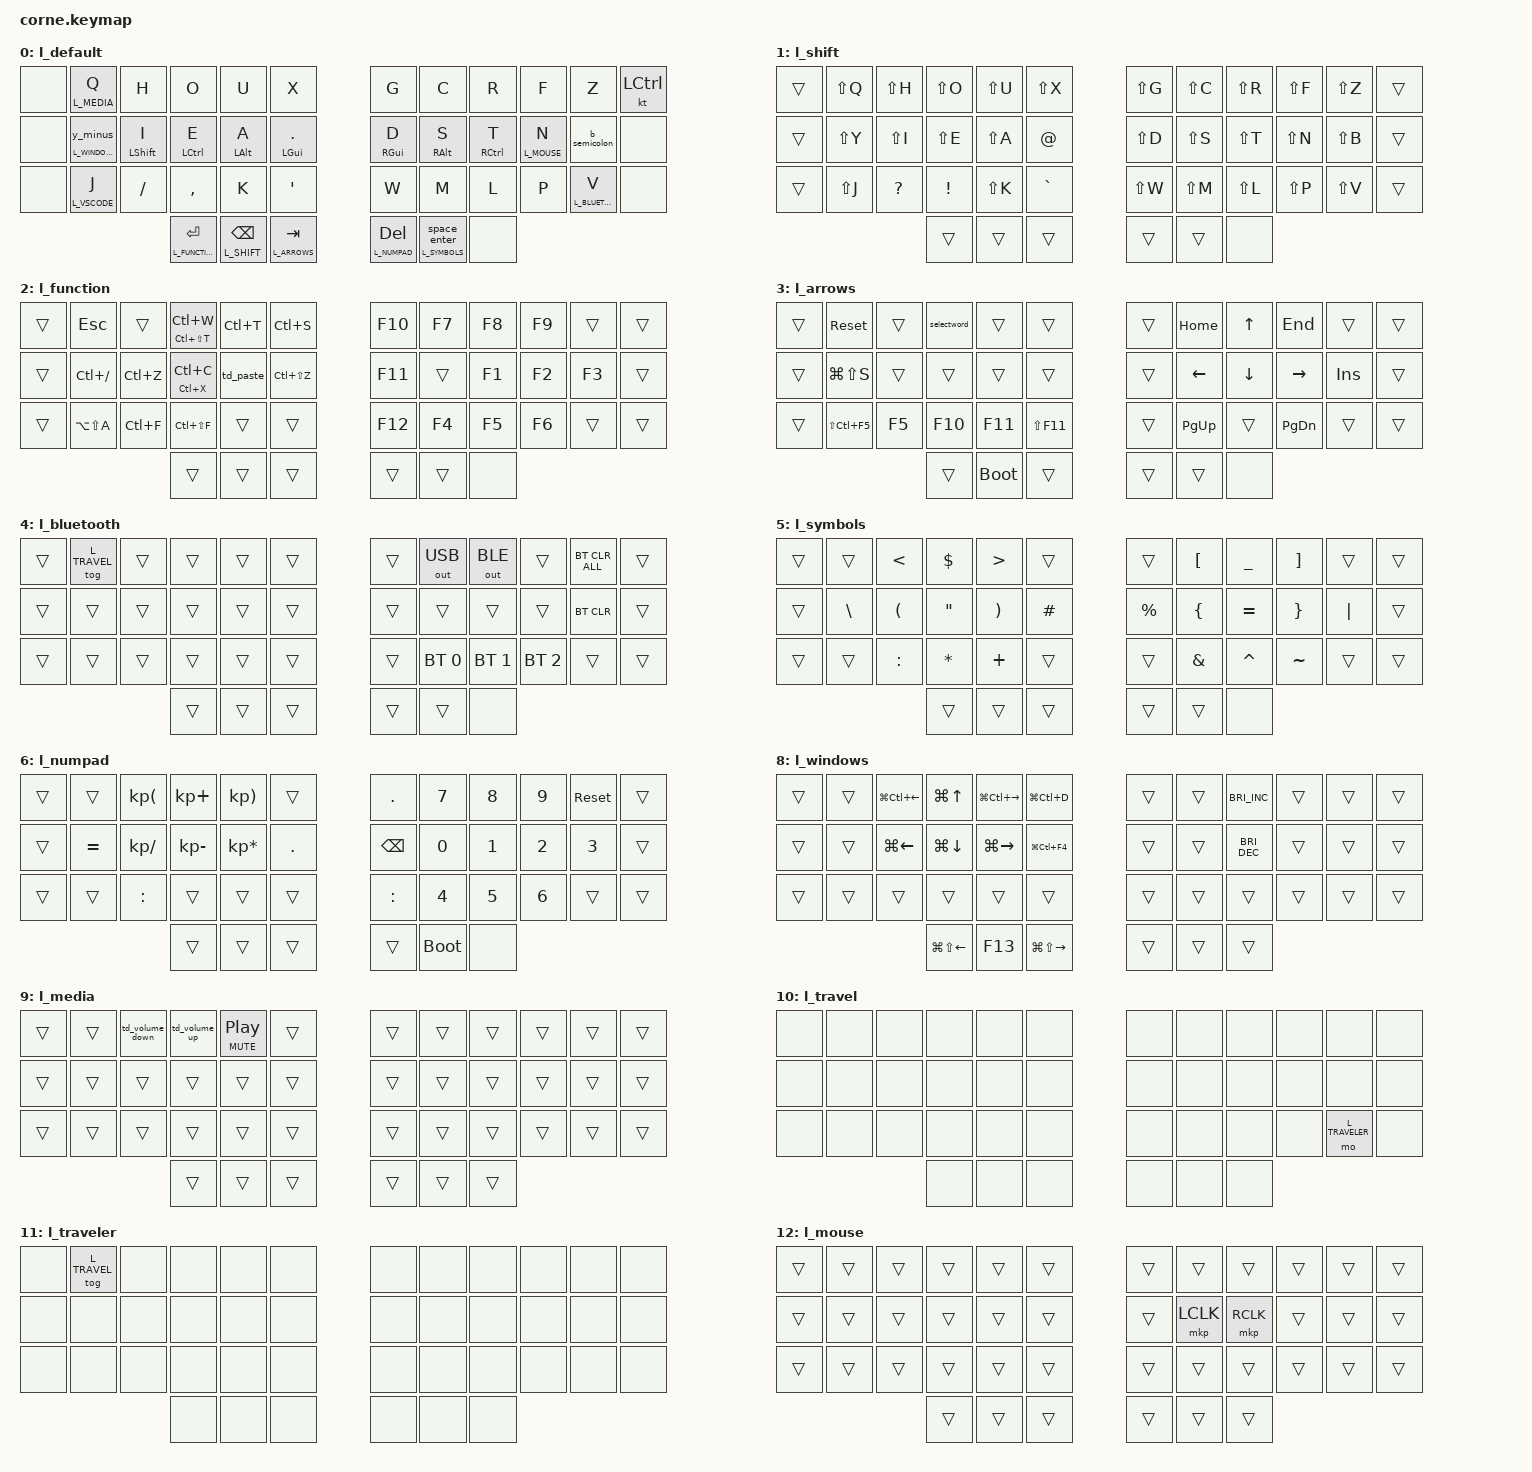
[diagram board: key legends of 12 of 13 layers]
/*
 * Copyright (c) 2020 The ZMK Contributors
 *
 * SPDX-License-Identifier: MIT
 */

#include <behaviors.dtsi>
#include <dt-bindings/zmk/keys.h> //https://zmk.dev/docs/codes
#include <dt-bindings/zmk/bt.h> //https://zmk.dev/docs/behaviors/bluetooth
#include <dt-bindings/zmk/ext_power.h> //https://zmk.dev/docs/behaviors/power
#include <dt-bindings/zmk/outputs.h> //https://zmk.dev/docs/behaviors/outputs
#include <dt-bindings/zmk/mouse.h> //https://zmk.dev/docs/behaviors/mouse-emulation

#define L_DEFAULT       0
#define L_SHIFT         1
#define L_FUNCTION      2
#define L_ARROWS        3
#define L_BLUETOOTH     4
#define L_SYMBOLS       5
#define L_NUMPAD        6
#define L_VSCODE        7
#define L_WINDOWS       8
#define L_MEDIA         9
#define L_TRAVEL       10
#define L_TRAVELER     11
#define L_MOUSE        12

&mt {
    tapping-term-ms = <200>; //default: 200
    flavor = "tap-preferred"; //default: hold-preferred
};
&lt {
    tapping-term-ms = <200>; //default: 200
    flavor = "hold-preferred"; //default: tap-preferred
    //quick-tap-ms = <200>; //allows backspace to be held by tapping and holding
    //FIXME: backspacing, followed by a hold (for the shift layer) behaves as a double backspace
};

/ {
        behaviors {
                //https://zmk.dev/docs/behaviors/hold-tap
                ht: hold_tap {
                        compatible = "zmk,behavior-hold-tap";
                        #binding-cells = <2>;
                        tapping-term-ms = <200>;
                        quick-tap-ms = <0>;
                        flavor = "tap-preferred";
                        bindings = <&kp>, <&kp>;
                };

                //https://zmk.dev/docs/behaviors/tap-dance
                td_paste: tap_dance_paste {
                        //single tap = paste, hold = clipboard history, double tap = paste without formatting
                        compatible = "zmk,behavior-tap-dance";
                        #binding-cells = <0>;
                        tapping-term-ms = <200>;
                        bindings = <&ht LC(LS(V)) LC(V)>, <&kp LG(V)>;
                };
                td_volume_up: tap_dance_volume_up {
                        //single tap = volume up, hold = next track, double tap = volume up
                        compatible = "zmk,behavior-tap-dance";
                        #binding-cells = <0>;
                        tapping-term-ms = <200>;
                        bindings = <&ht C_NEXT C_VOLUME_UP>, <&kp C_VOLUME_UP>;
                };
                td_volume_down: tap_dance_volume_down {
                        //single tap = volume down, hold = previous track, double tap = volume down
                        compatible = "zmk,behavior-tap-dance";
                        #binding-cells = <0>;
                        tapping-term-ms = <200>;
                        bindings = <&ht C_PREV C_VOLUME_DOWN>, <&kp C_VOLUME_DOWN>;
                };
                b_semicolon: b_semicolon {
                        compatible = "zmk,behavior-mod-morph";
                        #binding-cells = <0>;
                        bindings = <&kp B>, <&kp SEMICOLON>;
                        mods = <(MOD_LCTL)>;
                        keep-mods = <(MOD_RCTL)>;
                };
                y_minus: y_minus {
                        compatible = "zmk,behavior-mod-morph";
                        #binding-cells = <0>;
                        bindings = <&kp Y>, <&kp MINUS>;
                        mods = <(MOD_RCTL)>;
                        keep-mods = <(MOD_LCTL)>;
                };
                lt_y_minus: lt_y_minus {
                        compatible = "zmk,behavior-hold-tap";
                        label = "LT_Y_MINUS";
                        #binding-cells = <2>;
                        bindings = <&mo>, <&y_minus>;
                        tapping-term-ms = <200>;
                };
                space_enter: space_enter {
                        compatible = "zmk,behavior-mod-morph";
                        #binding-cells = <0>;
                        bindings = <&kp SPACE>, <&kp ENTER>;
                        mods = <(MOD_LCTL|MOD_RCTL)>;
                };
                lt_space_enter: lt_space_enter {
                        compatible = "zmk,behavior-hold-tap";
                        label = "LT_SPACE_ENTER";
                        #binding-cells = <2>;
                        bindings = <&mo>, <&space_enter>;
                        tapping-term-ms = <200>;
                };
        };

        macros {
                //https://zmk.dev/docs/behaviors/macros
                references: references {
                        compatible = "zmk,behavior-macro";
                        #binding-cells = <0>;
                        bindings
                                = <&macro_tap &kp LC(K) &kp LC(R)>
                                ;
                };
                prevbookmark: prevbookmark {
                        compatible = "zmk,behavior-macro";
                        #binding-cells = <0>;
                        bindings
                                = <&macro_tap &kp LC(B) &kp LC(P)>
                                ;
                };
                nextbookmark: nextbookmark {
                        compatible = "zmk,behavior-macro";
                        #binding-cells = <0>;
                        bindings
                                = <&macro_tap &kp LC(B) &kp LC(N)>
                                ;
                };
                selectword: selectword {
                        compatible = "zmk,behavior-macro";
                        #binding-cells = <0>;
                        bindings
                                = <&macro_tap &kp LC(LEFT) &kp LC(LS(RIGHT))>
                                ;
                };
    };

        keymap {
                compatible = "zmk,keymap";

                l_default {
// -----------------------------------------------------------------------------------------
// |   q   |  h  |  o  |  u  |  x  |                                        |  g  |  c  |  r  |  f  |  z  |
// |  y/-  |  i  |  e  |  a  |  .  |                                        |  d  |  s  |  t  |  n  | b/; |
// |   j   |  /  |  ,  |  k  |  '  |                                        |  w  |  m  |  l  |  p  |  v  |
//       | ENTER | BACKSPACE | TAB |                                        | DELETE | SPACE |
                        bindings = <
&none       &lt L_MEDIA Q               &kp H           &kp O                   &kp U                   &kp X                           &kp G                   &kp C                           &kp R                   &kp F           &kp Z               &kt LCTRL
&none       &lt_y_minus L_WINDOWS 0     &mt LSHFT I     &mt LCTRL E             &mt LALT A              &mt LGUI PERIOD                 &mt RGUI D              &mt RALT S                      &mt RCTRL T             &lt L_MOUSE N   &b_semicolon        &none
&none       &lt L_VSCODE J              &kp SLASH       &kp COMMA               &kp K                   &kp APOSTROPHE                  &kp W                   &kp M                           &kp L                   &kp P           &lt L_BLUETOOTH V   &none
                                                        &lt L_FUNCTION ENTER    &lt L_SHIFT BACKSPACE   &lt L_ARROWS TAB                &lt L_NUMPAD DELETE     &lt_space_enter L_SYMBOLS 0     &none
                        >;
                };
                l_shift {
// -----------------------------------------------------------------------------------------
// |  Q  |  H  |  O  |  U  |  X  |                                        |  G  |  C  |  R  |  F  |  Z  |
// |  Y  |  I  |  E  |  A  |  @  |                                        |  D  |  S  |  T  |  N  |  B  |
// |  J  |  ?  |  !  |  K  |  `  |                                        |  W  |  M  |  L  |  P  |  V  |
//             |     |  *  |     |                                        |     |     |
                        bindings = <
&trans  &kp LS(Q)       &kp LS(H)       &kp LS(O)       &kp LS(U)       &kp LS(X)               &kp LS(G)       &kp LS(C)       &kp LS(R)       &kp LS(F)       &kp LS(Z)       &trans
&trans  &kp LS(Y)       &kp LS(I)       &kp LS(E)       &kp LS(A)       &kp AT                  &kp LS(D)       &kp LS(S)       &kp LS(T)       &kp LS(N)       &kp LS(B)       &trans
&trans  &kp LS(J)       &kp QMARK       &kp EXCL        &kp LS(K)       &kp GRAVE               &kp LS(W)       &kp LS(M)       &kp LS(L)       &kp LS(P)       &kp LS(V)       &trans
                                        &trans          &trans          &trans                  &trans          &trans          &none
                        >;
                };
                l_function {
// -----------------------------------------------------------------------------------------
// |ESC            |       |CLOSE TAB              |NEW TAB        |SAVE        |               |F10|F7 |F8 |F9 |   |
// |LINE COMMENT   |UNDO   |COPY                   |PASTE          |REDO        |               |F11|   |F1 |F2 |F3 |
// |BLOCK COMMENT  |FIND   |FIND IN SOLUTION       |               |            |               |F12|F4 |F5 |F6 |   |
//                         |           *           |               |            |               |   |   |
                        bindings = <
&trans      &kp ESC          &trans          &ht LC(LS(T)) LC(W)     &kp LC(T)               &kp LC(S)               &kp F10 &kp F7  &kp F8  &kp F9  &trans  &trans
&trans      &kp LC(SLASH)   &kp LC(Z)       &ht LC(X) LC(C)         &td_paste               &kp LC(LS(Z))           &kp F11 &trans  &kp F1  &kp F2  &kp F3  &trans
&trans      &kp LA(LS(A))   &kp LC(F)       &kp LC(LS(F))           &trans                  &trans                  &kp F12 &kp F4  &kp F5  &kp F6  &trans  &trans
                                            &trans                  &trans                  &trans                  &trans  &trans  &none
                        >;
                };
                l_arrows {
// -----------------------------------------------------------------------------------------
// | RESET      |                | SELECT WORD |         |          |                        |    |HOME    |UP     |END       |       |
// | SCREENSHOT | SHIFT          | CTRL        | ALT     |          |                        |    |LEFT    |DOWN   |RIGHT     |INSERT |
// | RESTART    | DEBUG/CONTINUE | STEP        | STEP IN | STEP OUT |                        |    |PAGE UP |       |PAGE DOWN |       |
//                               |             | BOOT    |     *    |                        |    |        |
                        bindings = <
&trans  &sys_reset          &trans  &selectword     &trans        &trans                  &trans  &kp HOME        &kp UP          &kp END         &trans          &trans
&trans  &kp LG(LS(S))   &trans  &trans          &trans        &trans                  &trans  &kp LEFT        &kp DOWN        &kp RIGHT       &kp INSERT      &trans
&trans  &kp LS(LC(F5))  &kp F5  &kp F10         &kp F11       &kp LS(F11)             &trans  &kp PG_UP       &trans          &kp PG_DN       &trans          &trans
                                &trans          &bootloader   &trans                  &trans  &trans          &none
                        >;
                };

                l_bluetooth 
                {
                        //https://zmk.dev/docs/behaviors/bluetooth
// -----------------------------------------------------------------------------------------
// |TRAVEL TOG  |    |    |    |    |                        |    | USB   | BLE   |      | CLEAR ALL |
// |            |    |    |    |    |                        |    |       |       |      | CLEAR     |
// |            |    |    |    |    |                        |    | SEL 0 | SEL 1 | SEL2 |   *       |
//                   |    |    |    |                        |    |       |
                        bindings = <
&trans   &tog L_TRAVEL  &trans  &trans  &trans  &trans          &trans  &out OUT_USB    &out OUT_BLE     &trans         &bt BT_CLR_ALL   &trans
&trans   &trans         &trans  &trans  &trans  &trans          &trans  &trans          &trans           &trans         &bt BT_CLR       &trans
&trans   &trans         &trans  &trans  &trans  &trans          &trans  &bt BT_SEL 0    &bt BT_SEL 1     &bt BT_SEL 2   &trans           &trans
                                &trans  &trans  &trans          &trans  &trans  &none
                        >;
                };

                l_symbols {
// -----------------------------------------------------------------------------------------
// |     |  <  |  $  |  >  |     |                        |     |  [  |  _  |  ]  |     |
// |  \  |  (  |  "  |  )  |  #  |                        |  %  |  {  |  =  |  }  |  |  |
// |     |  :  |  *  |  +  |     |                        |     |  &  |  ^  |  ~  |     |
//             |     |     |     |                        |     |  *  |
                        bindings = <
&trans  &trans          &kp LESS_THAN           &kp DOLLAR              &kp GREATER_THAN        &trans                  &trans          &kp LEFT_BRACKET        &kp UNDERSCORE  &kp RIGHT_BRACKET       &trans          &trans
&trans  &kp BACKSLASH   &kp LEFT_PARENTHESIS    &kp DOUBLE_QUOTES       &kp RIGHT_PARENTHESIS   &kp POUND               &kp PERCENT     &kp LEFT_BRACE          &kp EQUAL       &kp RIGHT_BRACE         &kp PIPE        &trans
&trans  &trans          &kp COLON               &kp ASTERISK            &kp PLUS                &trans                  &trans          &kp AMPERSAND           &kp CARET       &kp TILDE               &trans          &trans
                                                &trans                  &trans                  &trans                  &trans          &trans                  &none
                        >;
                };
                l_numpad {
// -----------------------------------------------------------------------------------------
// |    | (  | +  | )  |    |                        | PERIOD      |  7  |  8  |  9  | RESET |
// | =  | /  | -  | *  | .  |                        | BACKSPACE   |  0  |  1  |  2  |  3    |
// |    | :  |    |    |    |                        | COLON       |  4  |  5  |  6  |       |
//           |    |    |    |                        |      *      | BOOT|
                        bindings = <
&trans  &trans     &kp KP_LPAR     &kp KP_PLUS     &kp KP_RPAR     &trans                  &kp PERIOD      &kp NUMBER_7    &kp NUMBER_8    &kp NUMBER_9    &sys_reset          &trans
&trans  &kp EQUAL  &kp KP_DIVIDE   &kp KP_MINUS    &kp KP_MULTIPLY &kp PERIOD              &kp BACKSPACE   &kp NUMBER_0    &kp NUMBER_1    &kp NUMBER_2    &kp NUMBER_3    &trans
&trans  &trans     &kp COLON       &trans          &trans          &trans                  &kp COLON       &kp NUMBER_4    &kp NUMBER_5    &kp NUMBER_6    &trans          &trans
                                   &trans          &trans          &trans                  &trans          &bootloader     &none
                        >;
                };
                l_vscode {
// -----------------------------------------------------------------------------------------
// |     |peef def          |references     |implementations        |    |                        |    |    |    |    |    |
// |     |back              |def            |forward                |    |                        |    |    |    |    |    |
// |  *  |prev bookmark     |bookmark       |next bookmark          |    |                        |    |    |    |    |    |
//                          |               |                       |    |                        |    |    |
                        bindings = <
&trans  &trans  &kp LA(F12)     &references                        &kp LC(F12)             &trans          &trans  &trans  &trans  &trans  &trans  &trans
&trans  &trans  &kp LA(LEFT)    &kp F12                            &kp LA(RIGHT)           &trans          &trans  &trans  &trans  &trans  &trans  &trans
&trans  &trans  &prevbookmark   &ht LA(LC(K)) LA(LC(LG(LS(K))))    &nextbookmark           &trans          &trans  &trans  &trans  &trans  &trans  &trans
                        &trans  &trans  &trans                                                             &trans  &trans  &trans
                        >;
                };
                l_windows {
// -----------------------------------------------------------------------------------------
// |     |VD left           |window up      |VD right       |new VD         |                        |    |    | BRIGHTNESS UP    |    |    |
// |  *  |window left       |window down    |window right   |exit VD        |                        |    |    | BRIGHTNESS DOWN  |    |    |
// |     |                  |               |               |               |                        |    |    |    |    |    |
//                          |monitor left   |task view      |monitor right  |                        |    |    |
                        bindings = <
&trans  &trans  &kp LG(LC(LEFT))        &kp LG(UP)      &kp LG(LC(RIGHT))       &kp LG(LC(D))           &trans  &trans  &kp C_BRI_INC  &trans  &trans  &trans
&trans  &trans  &kp LG(LEFT)            &kp LG(DOWN)    &kp LG(RIGHT)           &kp LG(LC(F4))          &trans  &trans  &kp C_BRI_DEC  &trans  &trans  &trans
&trans  &trans  &trans                  &trans          &trans                  &trans                  &trans  &trans  &trans  &trans  &trans  &trans
                        &kp LG(LS(LEFT))  &kp F13  &kp LG(LS(RIGHT))                                    &trans  &trans  &trans
                        >;
                };
                l_media {
// -----------------------------------------------------------------------------------------
// |   *   |VOL DOWN / PREV  |VOL UP / NEXT  |PLAY PAUSE / MUTE  |    |                        |    |    |    |    |    |
// |       |                 |               |                   |    |                        |    |    |    |    |    |
// |       |                 |               |                   |    |                        |    |    |    |    |    |
//                           |               |                   |    |                        |    |    |
                        bindings = <
&trans  &trans  &td_volume_down  &td_volume_up  &ht C_MUTE C_PLAY_PAUSE  &trans          &trans  &trans  &trans  &trans  &trans  &trans
&trans  &trans  &trans           &trans         &trans                   &trans          &trans  &trans  &trans  &trans  &trans  &trans
&trans  &trans  &trans           &trans         &trans                   &trans          &trans  &trans  &trans  &trans  &trans  &trans
                                 &trans         &trans                   &trans          &trans  &trans  &trans
                        >;
                };
                l_travel {
// -----------------------------------------------------------------------------------------
// |    |    |    |    |    |                        |    |    |    |    |          |
// |    |    |    |    |    |                        |    |    |    |    |          |
// |    |    |    |    |    |                        |    |    |    |    | TRAVELER |
//           |    |    |    |                        |    |    |
                        bindings = <
&none  &none  &none  &none  &none  &none          &none  &none  &none  &none  &none           &none
&none  &none  &none  &none  &none  &none          &none  &none  &none  &none  &none           &none
&none  &none  &none  &none  &none  &none          &none  &none  &none  &none  &mo L_TRAVELER  &none
                     &none  &none  &none          &none  &none  &none
                        >;
                };
                l_traveler {
// -----------------------------------------------------------------------------------------
// | TRAVEL TOG   |    |    |    |    |                        |    |    |    |    |     |
// |              |    |    |    |    |                        |    |    |    |    |     |
// |              |    |    |    |    |                        |    |    |    |    |  *  |
//                     |    |    |    |                        |    |    |
                        bindings = <
&none   &tog L_TRAVEL  &none  &none  &none  &none          &none  &none  &none  &none  &none  &none
&none   &none          &none  &none  &none  &none          &none  &none  &none  &none  &none  &none
&none   &none          &none  &none  &none  &none          &none  &none  &none  &none  &none  &none
                              &none  &none  &none          &none  &none  &none
                        >;
                };
                l_mouse {
// -----------------------------------------------------------------------------------------
// |    |    |    |    |    |                        |    |            |             |     |    |
// |    |    |    |    |    |                        |    | LEFT CLICK | RIGHT CLICK |  *  |    |
// |    |    |    |    |    |                        |    |            |             |     |    |
//           |    |    |    |                        |    |    |
                        bindings = <
&trans  &trans  &trans  &trans  &trans  &trans          &trans  &trans     &trans     &trans  &trans  &trans
&trans  &trans  &trans  &trans  &trans  &trans          &trans  &mkp LCLK  &mkp RCLK  &trans  &trans  &trans
&trans  &trans  &trans  &trans  &trans  &trans          &trans  &trans     &trans     &trans  &trans  &trans
                        &trans  &trans  &trans          &trans  &trans  &trans
                        >;
                };
        };
};
                //https://github.com/ftc/zmk/tree/mouse-ftc
//                l_template {
// -----------------------------------------------------------------------------------------
// |    |    |    |    |    |                        |    |    |    |    |    |
// |    |    |    |    |    |                        |    |    |    |    |    |
// |    |    |    |    |    |                        |    |    |    |    |    |
//           |    |    |    |                        |    |    |
//                        bindings = <
//&trans  &trans  &trans  &trans  &trans  &trans          &trans  &trans  &trans  &trans  &trans  &trans
//&trans  &trans  &trans  &trans  &trans  &trans          &trans  &trans  &trans  &trans  &trans  &trans
//&trans  &trans  &trans  &trans  &trans  &trans          &trans  &trans  &trans  &trans  &trans  &trans
//                        &trans  &trans  &trans          &trans  &trans  &trans
//                        >;
//                };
